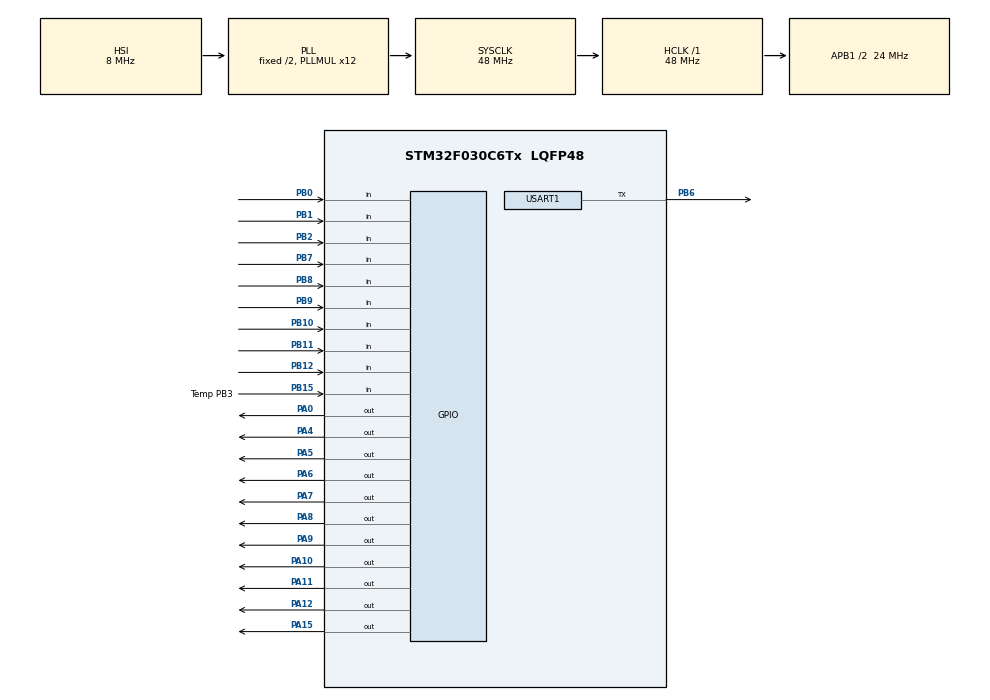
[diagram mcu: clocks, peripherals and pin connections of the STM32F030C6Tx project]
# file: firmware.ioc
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Dma.Request0=TIM1_CH3/UP
Dma.Request1=TIM1_CH4/TRIG/COM
Dma.TIM1_CH3/UP.0.Direction=DMA_MEMORY_TO_PERIPH
Dma.TIM1_CH3/UP.0.Instance=DMA1_Channel5
Dma.TIM1_CH3/UP.0.MemDataAlignment=DMA_MDATAALIGN_WORD
Dma.TIM1_CH3/UP.0.MemInc=DMA_MINC_ENABLE
Dma.TIM1_CH3/UP.0.Mode=DMA_CIRCULAR
Dma.TIM1_CH3/UP.0.PeriphDataAlignment=DMA_PDATAALIGN_WORD
Dma.TIM1_CH3/UP.0.PeriphInc=DMA_PINC_DISABLE
Dma.TIM1_CH3/UP.0.Priority=DMA_PRIORITY_MEDIUM
Dma.TIM1_CH4/TRIG/COM.1.Direction=DMA_PERIPH_TO_MEMORY
Dma.TIM1_CH4/TRIG/COM.1.Instance=DMA1_Channel4
Dma.TIM1_CH4/TRIG/COM.1.MemDataAlignment=DMA_MDATAALIGN_WORD
Dma.TIM1_CH4/TRIG/COM.1.MemInc=DMA_MINC_ENABLE
Dma.TIM1_CH4/TRIG/COM.1.Mode=DMA_CIRCULAR
Dma.TIM1_CH4/TRIG/COM.1.PeriphDataAlignment=DMA_PDATAALIGN_WORD
Dma.TIM1_CH4/TRIG/COM.1.PeriphInc=DMA_PINC_DISABLE
Dma.TIM1_CH4/TRIG/COM.1.Priority=DMA_PRIORITY_MEDIUM
Mcu.Family=STM32F0
Mcu.Name=STM32F030C6Tx
Mcu.Package=LQFP48
NVIC.DMA1_Channel4_5_IRQn=true\:1\:0\:true\:false\:true
NVIC.USART1_IRQn=true\:3\:0\:true\:false\:true
PA0.Signal=GPIO_Output
PA10.GPIO_PuPd=GPIO_NOPULL
PA10.Signal=GPIO_Output
PA11.GPIO_PuPd=GPIO_NOPULL
PA11.Signal=GPIO_Output
PA12.GPIO_PuPd=GPIO_NOPULL
PA12.Signal=GPIO_Output
PA13.Mode=Serial-WireDebug
PA13.Signal=SYS_SWDIO
PA14.Mode=Serial-WireDebug
PA14.Signal=SYS_SWCLK
PA15.GPIO_PuPd=GPIO_NOPULL
PA15.Signal=GPIO_Output
PA4.GPIO_PuPd=GPIO_NOPULL
PA4.Signal=GPIO_Output
PA5.GPIO_PuPd=GPIO_NOPULL
PA5.Signal=GPIO_Output
PA6.GPIO_PuPd=GPIO_NOPULL
PA6.Signal=GPIO_Output
PA7.GPIO_PuPd=GPIO_NOPULL
PA7.Signal=GPIO_Output
PA8.GPIO_PuPd=GPIO_NOPULL
PA8.Signal=GPIO_Output
PA9.GPIO_PuPd=GPIO_NOPULL
PA9.Signal=GPIO_Output
PB0.GPIO_PuPd=GPIO_PULLDOWN
PB0.Signal=GPIO_Input
PB1.GPIO_PuPd=GPIO_PULLDOWN
PB1.Signal=GPIO_Input
PB10.GPIO_PuPd=GPIO_PULLDOWN
PB10.Signal=GPIO_Input
PB11.GPIO_PuPd=GPIO_PULLDOWN
PB11.Signal=GPIO_Input
PB12.GPIO_PuPd=GPIO_PULLDOWN
PB12.Signal=GPIO_Input
PB15.GPIO_Label=Temp PB3
PB15.GPIO_PuPd=GPIO_PULLDOWN
PB15.Signal=GPIO_Input
PB2.GPIO_PuPd=GPIO_PULLDOWN
PB2.Signal=GPIO_Input
PB6.GPIO_Speed=GPIO_SPEED_FREQ_LOW
PB6.Mode=Half_duplex(single_wire_mode)
PB6.Signal=USART1_TX
PB7.GPIO_PuPd=GPIO_PULLDOWN
PB7.Signal=GPIO_Input
PB8.GPIO_PuPd=GPIO_PULLDOWN
PB8.Signal=GPIO_Input
PB9.GPIO_PuPd=GPIO_PULLDOWN
PB9.Signal=GPIO_Input
ProjectManager.HeapSize=0x200
ProjectManager.StackSize=0x400
ProjectManager.TargetToolchain=MDK-ARM V5
RCC.AHBFreq_Value=48000000
RCC.APB1CLKDivider=RCC_HCLK_DIV2
RCC.APB1Freq_Value=24000000
RCC.APB1TimFreq_Value=48000000
RCC.HCLKFreq_Value=48000000
RCC.PLLMUL=RCC_PLL_MUL12
RCC.SYSCLKFreq_VALUE=48000000
RCC.SYSCLKSource=RCC_SYSCLKSOURCE_PLLCLK
TIM1.Channel-Output\ Compare4\ No\ Output=TIM_CHANNEL_4
USART1.BaudRate=115200
USART1.Mode=UART_MODE_TX
USART1.OneBitSampling=UART_ONE_BIT_SAMPLE_DISABLE
VP_TIM1_VS_ClockSourceINT.Mode=Internal
VP_TIM1_VS_no_output4.Mode=Output Compare4 No Output
board=firmware

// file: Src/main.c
/**
  ******************************************************************************
  * File Name          : main.c
  * Description        : Main program body
  ******************************************************************************
  *
  * COPYRIGHT(c) 2016 STMicroelectronics
  *
  * Redistribution and use in source and binary forms, with or without modification,
  * are permitted provided that the following conditions are met:
  *   1. Redistributions of source code must retain the above copyright notice,
  *      this list of conditions and the following disclaimer.
  *   2. Redistributions in binary form must reproduce the above copyright notice,
  *      this list of conditions and the following disclaimer in the documentation
  *      and/or other materials provided with the distribution.
  *   3. Neither the name of STMicroelectronics nor the names of its contributors
  *      may be used to endorse or promote products derived from this software
  *      without specific prior written permission.
  *
  * THIS SOFTWARE IS PROVIDED BY THE COPYRIGHT HOLDERS AND CONTRIBUTORS "AS IS"
  * AND ANY EXPRESS OR IMPLIED WARRANTIES, INCLUDING, BUT NOT LIMITED TO, THE
  * IMPLIED WARRANTIES OF MERCHANTABILITY AND FITNESS FOR A PARTICULAR PURPOSE ARE
  * DISCLAIMED. IN NO EVENT SHALL THE COPYRIGHT HOLDER OR CONTRIBUTORS BE LIABLE
  * FOR ANY DIRECT, INDIRECT, INCIDENTAL, SPECIAL, EXEMPLARY, OR CONSEQUENTIAL
  * DAMAGES (INCLUDING, BUT NOT LIMITED TO, PROCUREMENT OF SUBSTITUTE GOODS OR
  * SERVICES; LOSS OF USE, DATA, OR PROFITS; OR BUSINESS INTERRUPTION) HOWEVER
  * CAUSED AND ON ANY THEORY OF LIABILITY, WHETHER IN CONTRACT, STRICT LIABILITY,
  * OR TORT (INCLUDING NEGLIGENCE OR OTHERWISE) ARISING IN ANY WAY OUT OF THE USE
  * OF THIS SOFTWARE, EVEN IF ADVISED OF THE POSSIBILITY OF SUCH DAMAGE.
  *
  ******************************************************************************
  */
#include "stm32f0xx_hal.h"
#include "dma.h"
#include "tim.h"
#include "usart.h"
#include "gpio.h"

/* USER CODE BEGIN PV */
/* Private variables ---------------------------------------------------------*/

/* USER CODE END PV */

void SystemClock_Config(void);

/* USER CODE BEGIN PFP */
/* Private function prototypes -----------------------------------------------*/

/* USER CODE END PFP */

int main(void)
{

  /* USER CODE BEGIN 1 */
  void user_main(void);
  /* USER CODE END 1 */

  /* MCU Configuration----------------------------------------------------------*/

  /* Reset of all peripherals, Initializes the Flash interface and the Systick. */
  HAL_Init();

  /* Configure the system clock */
  SystemClock_Config();

  /* Initialize all configured peripherals */
  MX_GPIO_Init();
  MX_DMA_Init();
  MX_TIM1_Init();
  MX_USART1_UART_Init();

  /* USER CODE BEGIN 2 */
  user_main();
  /* USER CODE END 2 */

  /* Infinite loop */
  while (1)
  {

  }

}

/** System Clock Configuration
*/
void SystemClock_Config(void)
{

  RCC_OscInitTypeDef RCC_OscInitStruct;
  RCC_ClkInitTypeDef RCC_ClkInitStruct;
  RCC_PeriphCLKInitTypeDef PeriphClkInit;

  RCC_OscInitStruct.OscillatorType = RCC_OSCILLATORTYPE_HSI;
  RCC_OscInitStruct.HSIState = RCC_HSI_ON;
  RCC_OscInitStruct.HSICalibrationValue = 16;
  RCC_OscInitStruct.PLL.PLLState = RCC_PLL_ON;
  RCC_OscInitStruct.PLL.PLLSource = RCC_PLLSOURCE_HSI;
  RCC_OscInitStruct.PLL.PLLMUL = RCC_PLL_MUL12;
  RCC_OscInitStruct.PLL.PREDIV = RCC_PREDIV_DIV1;
  HAL_RCC_OscConfig(&RCC_OscInitStruct);

  RCC_ClkInitStruct.ClockType = RCC_CLOCKTYPE_HCLK|RCC_CLOCKTYPE_SYSCLK
                              |RCC_CLOCKTYPE_PCLK1;
  RCC_ClkInitStruct.SYSCLKSource = RCC_SYSCLKSOURCE_PLLCLK;
  RCC_ClkInitStruct.AHBCLKDivider = RCC_SYSCLK_DIV1;
  RCC_ClkInitStruct.APB1CLKDivider = RCC_HCLK_DIV2;
  HAL_RCC_ClockConfig(&RCC_ClkInitStruct, FLASH_LATENCY_1);

  PeriphClkInit.PeriphClockSelection = RCC_PERIPHCLK_USART1;
  PeriphClkInit.Usart1ClockSelection = RCC_USART1CLKSOURCE_PCLK1;
  HAL_RCCEx_PeriphCLKConfig(&PeriphClkInit);

  HAL_SYSTICK_Config(HAL_RCC_GetHCLKFreq()/1000);

  HAL_SYSTICK_CLKSourceConfig(SYSTICK_CLKSOURCE_HCLK);

  /* SysTick_IRQn interrupt configuration */
  HAL_NVIC_SetPriority(SysTick_IRQn, 2, 0);
}

/************************ (C) COPYRIGHT STMicroelectronics *****END OF FILE****/
